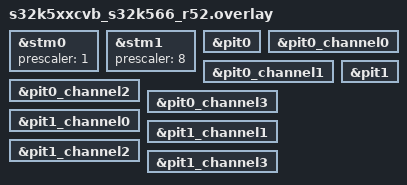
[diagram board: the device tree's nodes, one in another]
/*
 * Copyright 2025 NXP
 *
 * SPDX-License-Identifier: Apache-2.0
 */

&stm0 {
	prescaler = <1>;
	status = "okay";
};

&stm1 {
	prescaler = <8>;
	status = "okay";
};

&pit0 {
	status = "okay";
};

&pit0_channel0 {
	status = "okay";
};

&pit0_channel1 {
	status = "okay";
};

&pit0_channel2 {
	status = "okay";
};

&pit0_channel3 {
	status = "okay";
};

&pit1 {
	status = "okay";
};

&pit1_channel0 {
	status = "okay";
};

&pit1_channel1 {
	status = "okay";
};

&pit1_channel2 {
	status = "okay";
};

&pit1_channel3 {
	status = "okay";
};
